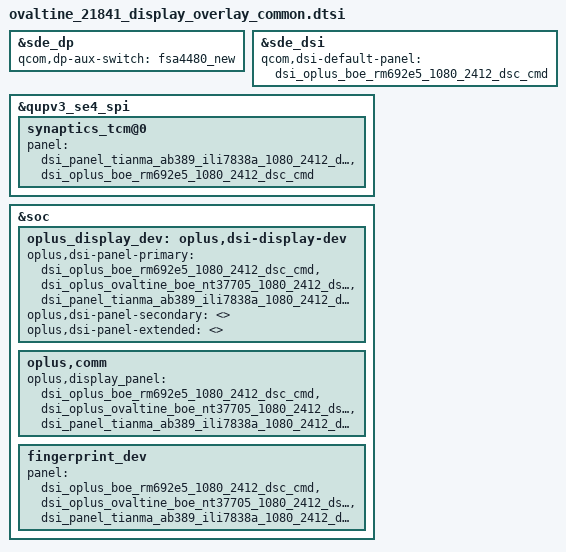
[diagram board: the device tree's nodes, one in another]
#include "../display/dsi_panel_oplus_boe_rm692e5_1080_2412_dsc_cmd.dtsi"
#include "../display/dsi-panel-oplus-ovaltine_boe_nt37705_1080_2412_dsc_cmd.dtsi"
#include "../display/dsi_panel_oplus_tianma_ab389_ili7838a_1080_2412_dsc_cmd.dtsi"

&sde_dp {
	qcom,dp-aux-switch = <&fsa4480_new>;
};

&sde_dsi {
	qcom,dsi-default-panel = <&dsi_oplus_boe_rm692e5_1080_2412_dsc_cmd>;
};

&qupv3_se4_spi {
	synaptics_tcm@0 {
		panel = <&dsi_panel_tianma_ab389_ili7838a_1080_2412_dsc_cmd
			&dsi_oplus_boe_rm692e5_1080_2412_dsc_cmd>;
	};
};

&soc {
	oplus_display_dev: oplus,dsi-display-dev {
		oplus,dsi-panel-primary = <
			&dsi_oplus_boe_rm692e5_1080_2412_dsc_cmd
			&dsi_oplus_ovaltine_boe_nt37705_1080_2412_dsc_cmd
			&dsi_panel_tianma_ab389_ili7838a_1080_2412_dsc_cmd
		>;
		oplus,dsi-panel-secondary = <>;
		oplus,dsi-panel-extended = <>;
	};

	oplus,comm {
		oplus,display_panel = <
			&dsi_oplus_boe_rm692e5_1080_2412_dsc_cmd
			&dsi_oplus_ovaltine_boe_nt37705_1080_2412_dsc_cmd
			&dsi_panel_tianma_ab389_ili7838a_1080_2412_dsc_cmd
		>;
	};

	fingerprint_dev {
		panel = <&dsi_oplus_boe_rm692e5_1080_2412_dsc_cmd
			&dsi_oplus_ovaltine_boe_nt37705_1080_2412_dsc_cmd
			&dsi_panel_tianma_ab389_ili7838a_1080_2412_dsc_cmd>;
	};
};
